# ESP32-C6 register map
Vendor: ESPRESSIF SYSTEMS (SHANGHAI) CO., LTD.; Series: ESP32 C-Series; File version: 12
CPU: RV32IMAC r0p0, little endian, no MPU, no FPU, 0 interrupt priority bits
Address unit: 32 bits
Registers are 32-bit, read-write, reset 0x0 unless marked. A register's access mark holds for its fields unless they carry their own. Offsets are from the block's base; [hi:lo] are bit positions; {n}, {i} and the like mark numbered series.

## GPIO_SD — Sigma-Delta Modulation
Base 0x60091F00
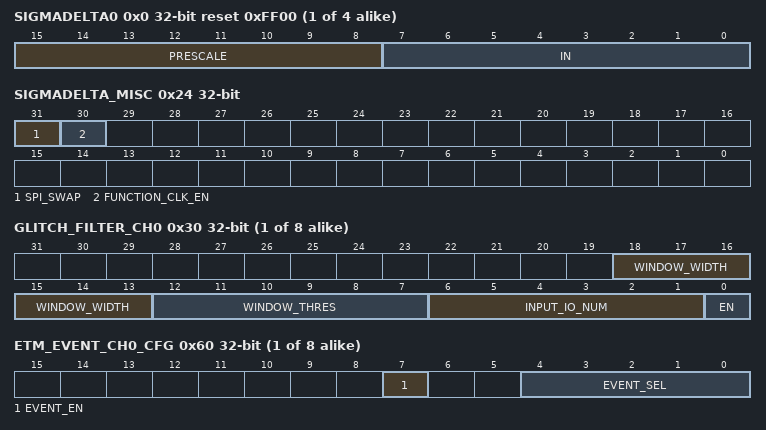
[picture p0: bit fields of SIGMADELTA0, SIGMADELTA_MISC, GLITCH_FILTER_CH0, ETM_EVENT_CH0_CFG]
{0x0+4i} SIGMADELTA{i} (i=0..3) reset 0xFF00 — Duty Cycle Configure Register of SDM{i}
  [15:8] PRESCALE — This field is used to set a divider value to divide APB clock.
  [7:0] IN — This field is used to configure the duty cycle of sigma delta modulation output.
0x20 CLOCK_GATE — Clock Gating Configure Register
  [0] CLK_EN — Clock enable bit of configuration registers for sigma delta modulation.
0x24 SIGMADELTA_MISC — MISC Register
  [31] SPI_SWAP — Reserved.
  [30] FUNCTION_CLK_EN — Clock enable bit of sigma delta modulation.
{0x30+4i} GLITCH_FILTER_CH{i} (i=0..7) — Glitch Filter Configure Register of Channel{i}
  [18:13] WINDOW_WIDTH — Glitch Filter window width.
  [12:7] WINDOW_THRES — Glitch Filter window threshold.
  [6:1] INPUT_IO_NUM — Glitch Filter input io number.
  [0] EN — Glitch Filter channel enable bit.
{0x60+4i} ETM_EVENT_CH{i}_CFG (i=0..7) — Etm Config register of Channel{i}
  [7] EVENT_EN — Etm event send enable bit.
  [4:0] EVENT_SEL — Etm event channel select gpio.
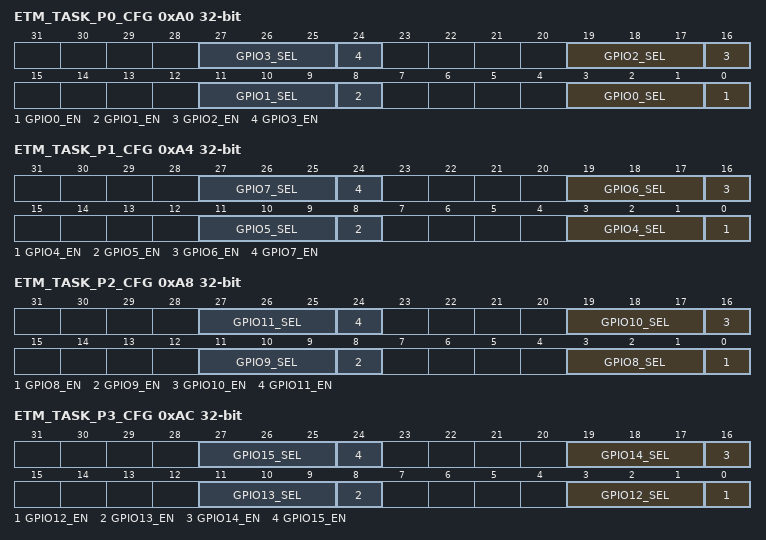
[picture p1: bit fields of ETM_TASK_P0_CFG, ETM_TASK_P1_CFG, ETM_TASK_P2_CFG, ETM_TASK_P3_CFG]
0xA0 ETM_TASK_P0_CFG — Etm Configure Register to decide which GPIO been chosen
  [8n+3:8n+1] GPIO{n}_SEL (n=0..3) — GPIO choose a etm task channel.
  [8n] GPIO{n}_EN (n=0..3) — Enable bit of GPIO response etm task.
0xA4 ETM_TASK_P1_CFG — Etm Configure Register to decide which GPIO been chosen
  [8n-29:8n-31] GPIO{n}_SEL (n=4..7) — GPIO choose a etm task channel.
  [8n-32] GPIO{n}_EN (n=4..7) — Enable bit of GPIO response etm task.
0xA8 ETM_TASK_P2_CFG — Etm Configure Register to decide which GPIO been chosen
  [8n-61:8n-63] GPIO{n}_SEL (n=8..11) — GPIO choose a etm task channel.
  [8n-64] GPIO{n}_EN (n=8..11) — Enable bit of GPIO response etm task.
0xAC ETM_TASK_P3_CFG — Etm Configure Register to decide which GPIO been chosen
  [8n-93:8n-95] GPIO{n}_SEL (n=12..15) — GPIO choose a etm task channel.
  [8n-96] GPIO{n}_EN (n=12..15) — Enable bit of GPIO response etm task.
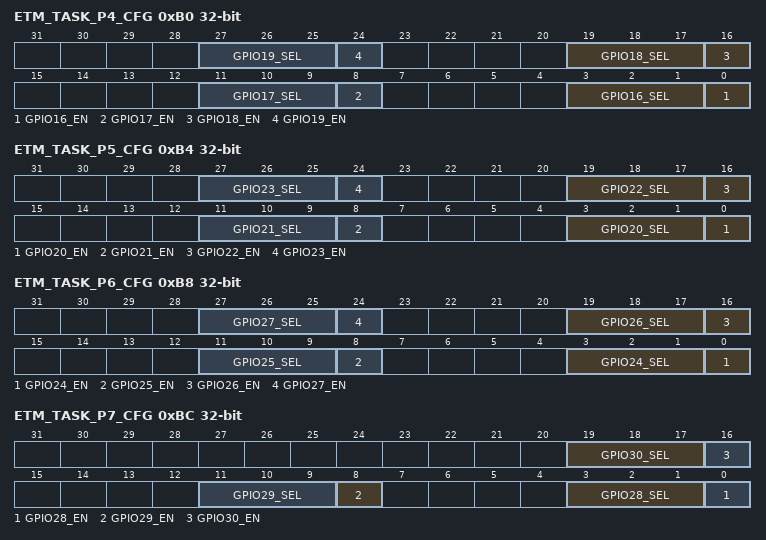
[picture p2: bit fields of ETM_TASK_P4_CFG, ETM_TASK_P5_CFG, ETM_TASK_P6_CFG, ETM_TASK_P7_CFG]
0xB0 ETM_TASK_P4_CFG — Etm Configure Register to decide which GPIO been chosen
  [8n-125:8n-127] GPIO{n}_SEL (n=16..19) — GPIO choose a etm task channel.
  [8n-128] GPIO{n}_EN (n=16..19) — Enable bit of GPIO response etm task.
0xB4 ETM_TASK_P5_CFG — Etm Configure Register to decide which GPIO been chosen
  [8n-157:8n-159] GPIO{n}_SEL (n=20..23) — GPIO choose a etm task channel.
  [8n-160] GPIO{n}_EN (n=20..23) — Enable bit of GPIO response etm task.
0xB8 ETM_TASK_P6_CFG — Etm Configure Register to decide which GPIO been chosen
  [8n-189:8n-191] GPIO{n}_SEL (n=24..27) — GPIO choose a etm task channel.
  [8n-192] GPIO{n}_EN (n=24..27) — Enable bit of GPIO response etm task.
0xBC ETM_TASK_P7_CFG — Etm Configure Register to decide which GPIO been chosen
  [8n-221:8n-223] GPIO{n}_SEL (n=28..30) — GPIO choose a etm task channel.
  [8n-224] GPIO{n}_EN (n=28..30) — Enable bit of GPIO response etm task.
0xFC VERSION — Version Control Register

## HMAC — HMAC (Hash-based Message Authentication Code) Accelerator
Base 0x6008D000
0x40 SET_START wo — Process control register 0.
  [0] SET_START — Start hmac operation.
0x44 SET_PARA_PURPOSE wo — Configure purpose.
  [3:0] PURPOSE_SET — Set hmac parameter purpose.
0x48 SET_PARA_KEY wo — Configure key.
  [2:0] KEY_SET — Set hmac parameter key.
0x4C SET_PARA_FINISH wo — Finish initial configuration.
  [0] SET_PARA_END — Finish hmac configuration.
0x50 SET_MESSAGE_ONE wo — Process control register 1.
  [0] SET_TEXT_ONE — Call SHA to calculate one message block.
0x54 SET_MESSAGE_ING wo — Process control register 2.
  [0] SET_TEXT_ING — Continue typical hmac.
0x58 SET_MESSAGE_END wo — Process control register 3.
  [0] SET_TEXT_END — Start hardware padding.
0x5C SET_RESULT_FINISH wo — Process control register 4.
  [0] SET_RESULT_END — After read result from upstream, then let hmac back to idle.
0x60 SET_INVALIDATE_JTAG wo — Invalidate register 0.
  [0] SET_INVALIDATE_JTAG — Clear result from hmac downstream JTAG.
0x64 SET_INVALIDATE_DS wo — Invalidate register 1.
  [0] SET_INVALIDATE_DS — Clear result from hmac downstream DS.
0x68 QUERY_ERROR ro — Error register.
  [0] QUERY_CHECK — Hmac configuration state. 0: key are agree with purpose. 1: error
0x6C QUERY_BUSY ro — Busy register.
  [0] BUSY_STATE — Hmac state. 1'b0: idle. 1'b1: busy
{0x80+4i} WR_MESSAGE_MEM[{i}] (i=0..15) access not given — Message block memory.
{0xC0+4i} RD_RESULT_MEM[{i}] (i=0..7) access not given — Result from upstream.
0xF0 SET_MESSAGE_PAD wo — Process control register 5.
  [0] SET_TEXT_PAD — Start software padding.
0xF4 ONE_BLOCK wo — Process control register 6.
  [0] SET_ONE_BLOCK — Don't have to do padding.
0xF8 SOFT_JTAG_CTRL wo — Jtag register 0.
  [0] SOFT_JTAG_CTRL — Turn on JTAG verification.
0xFC WR_JTAG wo — Jtag register 1.
  [31:0] WR_JTAG — 32-bit of key to be compared.
0x1FC DATE
